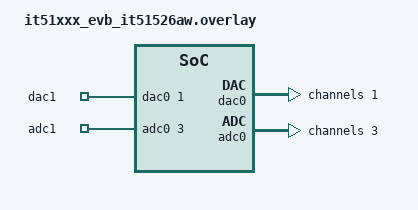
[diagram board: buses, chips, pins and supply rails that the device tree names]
/*
 * Copyright (c) 2026 ITE Corporation. All Rights Reserved.
 *
 * SPDX-License-Identifier: Apache-2.0
 */

/* Connect DAC0 (GPJ1) to ADC3 (GPI3) with a jumper for this test. */

/ {
	zephyr,user {
		io-channels = <&dac0 1>, <&adc0 3>;
		io-channel-names = "dac1", "adc1";
	};
};

&dac0 {
	pinctrl-0 = <&dac0_ch1_gpj1_default>;

	channel@1 {
		reg = <1>;
		zephyr,resolution = <8>;
	};
};

&adc0 {
	#address-cells = <1>;
	#size-cells = <0>;

	channel@3 {
		reg = <3>;
		zephyr,gain = "ADC_GAIN_1";
		zephyr,reference = "ADC_REF_INTERNAL";
		zephyr,acquisition-time = <ADC_ACQ_TIME_DEFAULT>;
		zephyr,resolution = <12>;
	};
};
